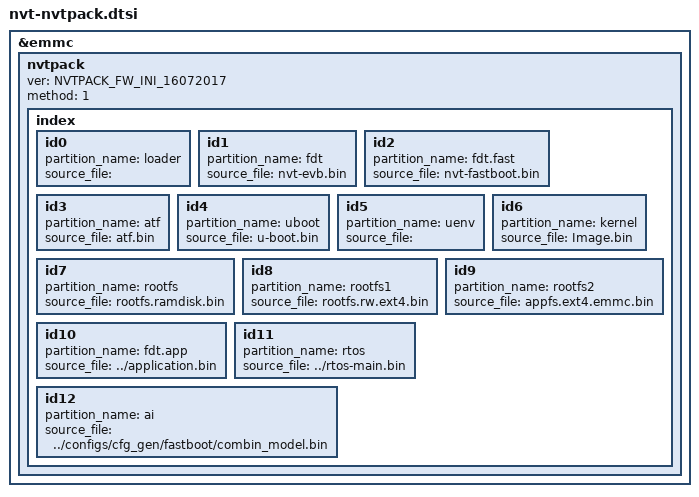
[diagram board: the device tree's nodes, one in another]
/*
 * Novatek Ltd. BSP part of dts
 */

&emmc {
	nvtpack {
		ver = "NVTPACK_FW_INI_16072017"; /* Fixed */
		method = <1>; /* Fixed */
		index {
			id0 { partition_name = "loader";      source_file = ""; }; /* Fixed */
			id1 { partition_name = "fdt";         source_file = "nvt-evb.bin"; }; /* Fixed */
			id2 { partition_name = "fdt.fast";    source_file = "nvt-fastboot.bin";	}; /* Fixed */
			id3 { partition_name = "atf";         source_file = "atf.bin"; };
			id4 { partition_name = "uboot";	      source_file = "u-boot.bin"; };
			id5 { partition_name = "uenv";	      source_file = ""; };
			id6 { partition_name = "kernel";      source_file = "Image.bin"; };
			id7 { partition_name = "rootfs";      source_file = "rootfs.ramdisk.bin"; };
			id8 { partition_name = "rootfs1";     source_file = "rootfs.rw.ext4.bin"; };
			id9 { partition_name = "rootfs2";     source_file = "appfs.ext4.emmc.bin"; };
			id10 { partition_name = "fdt.app";    source_file = "../application.bin"; };
			id11 { partition_name = "rtos";       source_file = "../rtos-main.bin"; };
			id12 { partition_name = "ai";         source_file = "../configs/cfg_gen/fastboot/combin_model.bin"; };
		};
	};
};

